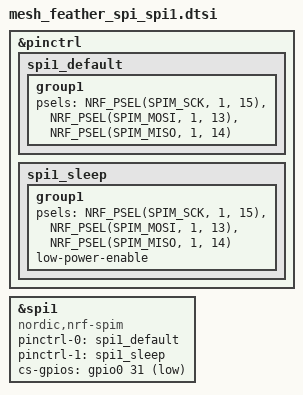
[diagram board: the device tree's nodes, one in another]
/*
 * Copyright (c) 2018 Peter Bigot Consulting, LLC
 *
 * SPDX-License-Identifier: Apache-2.0
 */

/* Add SPI support on Particle Mesh via nRF52840 SPI1
 *
 * NOTE: This file is replicated in particle_{argon,xenon}.
 * Changes should be made in all instances.
 */

&pinctrl {
	spi1_default: spi1_default {
		group1 {
			psels = <NRF_PSEL(SPIM_SCK, 1, 15)>,
				<NRF_PSEL(SPIM_MOSI, 1, 13)>,
				<NRF_PSEL(SPIM_MISO, 1, 14)>;
		};
	};

	spi1_sleep: spi1_sleep {
		group1 {
			psels = <NRF_PSEL(SPIM_SCK, 1, 15)>,
				<NRF_PSEL(SPIM_MOSI, 1, 13)>,
				<NRF_PSEL(SPIM_MISO, 1, 14)>;
			low-power-enable;
		};
	};
};

feather_spi: &spi1 { /* feather SPI */
	compatible = "nordic,nrf-spim";
	status = "okay";
	pinctrl-0 = <&spi1_default>;
	pinctrl-1 = <&spi1_sleep>;
	pinctrl-names = "default", "sleep";
	cs-gpios = <&gpio0 31 GPIO_ACTIVE_LOW>;
};

